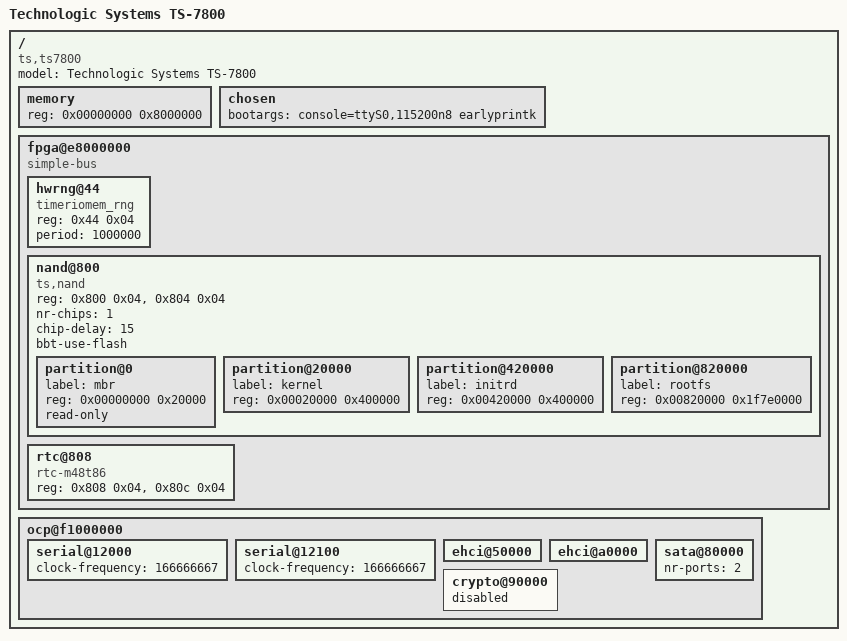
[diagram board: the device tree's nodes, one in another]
/*
 * Copyright (C) 2013 Alexander Clouter <alex@digriz.org.uk>
 *
 * This file is licensed under the terms of the GNU General Public
 * License version 2. This program is licensed "as is" without any
 * warranty of any kind, whether express or implied.
 */

/dts-v1/;
/include/ "orion5x.dtsi"

/ {
	model = "Technologic Systems TS-7800";
	compatible = "ts,ts7800", "marvell,orion5x-88f5182", "marvell,orion5x";

	memory {
		reg = <0x00000000 0x8000000>; /* 128 MB */
	};

	chosen {
		bootargs = "console=ttyS0,115200n8 earlyprintk";
	};

	fpga@e8000000 {
		#address-cells = <1>;
		#size-cells = <1>;
		compatible = "simple-bus";
		ranges = <0x00000000 0xe8000000 0x10000000>;

		hwrng@44 {
			#address-cells = <1>;
			#size-cells = <1>;
			compatible = "timeriomem_rng";
			reg = <0x44 0x04>;
			period = <1000000>;
		};

		nand@800 {
			#address-cells = <1>;
			#size-cells = <1>;
			compatible = "ts,nand", "gen_nand";
			reg =	<0x800 0x04>,
				<0x804 0x04>;
			reg-names = "nand_ctrl", "nand_data";
			nr-chips = <1>;
			chip-delay = <15>;
			bbt-use-flash;

			partition@0 {
				label = "mbr";
				reg = <0x00000000 0x20000>;
				read-only;
			};

			partition@20000 {
				label = "kernel";
				reg = <0x00020000 0x400000>;
			};

			partition@420000 {
				label = "initrd";
				reg = <0x00420000 0x400000>;
			};

			partition@820000 {
				label = "rootfs";
				reg = <0x00820000 0x1f7e0000>;
			};
		};

		rtc@808 {
			#address-cells = <1>;
			#size-cells = <1>;
			compatible = "rtc-m48t86";
			reg =   <0x808 0x04>,
				<0x80c 0x04>;
			reg-names = "rtc_index", "rtc_data";
		};
	};

	ocp@f1000000 {
		serial@12000 {
			clock-frequency = <166666667>;
			status = "okay";
		};

		serial@12100 {
			clock-frequency = <166666667>;
			status = "okay";
		};

		ehci@50000 {
			status = "okay";
		};

		ehci@a0000 {
			status = "okay";
		};

		sata@80000 {
			status = "okay";
			nr-ports = <2>;
		};

		/* disable crypto as it crashes the board */
		crypto@90000 {
			status = "disabled";
		};
	};
};
